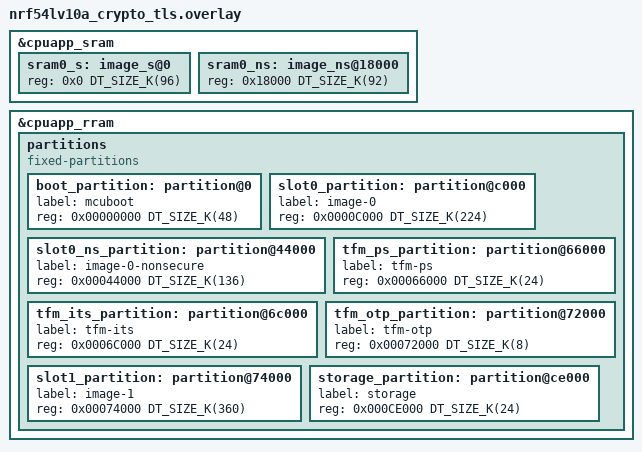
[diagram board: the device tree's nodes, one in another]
/*
 * Copyright (c) 2026 Nordic Semiconductor ASA
 *
 * SPDX-License-Identifier: LicenseRef-Nordic-5-Clause
 */

/*
 * Crypto/TLS-heavy TF-M partition layout for nRF54LV10A
 *
 * nRF54LV10A has 1012 kB of RRAM and 192 kB of SRAM.
 * TrustZone flash region alignment: 4 kB (MPC-based)
 * TrustZone RAM region alignment:   4 kB
 * RRAM erase-block-size:            4 kB
 *
 * Optimized for TLS/DTLS-heavy applications:
 * - Enlarged PS for X.509 certificate chains
 * - Enlarged ITS for TLS session keys and PSKs
 * - Full TF-M crypto for TLS 1.2/1.3
 * - MCUboot for secure firmware updates
 *
 * Suitable for: cloud-connected devices, HTTPS clients, MQTT+TLS
 */

&cpuapp_sram {
	sram0_s: image_s@0 {
		#address-cells = <1>;
		#size-cells = <1>;
		reg = <0x0 DT_SIZE_K(96)>;
		ranges = <0x0 0x0 DT_SIZE_K(96)>;
	};

	/* 92 kB NS — 4 kB unused at top */
	sram0_ns: image_ns@18000 {
		#address-cells = <1>;
		#size-cells = <1>;
		reg = <0x18000 DT_SIZE_K(92)>;
		ranges = <0x0 0x18000 DT_SIZE_K(92)>;
	};
};

&cpuapp_rram {
	partitions {
		compatible = "fixed-partitions";
		#address-cells = <1>;
		#size-cells = <1>;

		/*
		 * Flash layout (all addresses 4 kB aligned):
		 *
		 * 0x00000000  MCUboot bootloader        (48 kB)
		 * 0x0000C000  Primary slot:
		 *   0x0000C000  TF-M secure image       (224 kB)
		 *   0x00044000  Non-secure application   (136 kB)
		 * 0x00066000  TF-M PS                    (24 kB)
		 *             (enlarged for X.509 certificate chains)
		 * 0x0006C000  TF-M ITS                   (24 kB)
		 *             (enlarged for TLS session keys, PSKs)
		 * 0x00072000  TF-M OTP / NV counters      (8 kB)
		 * 0x00074000  Secondary slot            (360 kB)
		 * 0x000CE000  Non-secure storage         (24 kB)
		 *
		 * Primary = 224 + 136 = 360 kB = Secondary
		 * Total: 48 + 360 + 24 + 24 + 8 + 360 + 24 = 848 kB
		 */

		boot_partition: partition@0 {
			label = "mcuboot";
			reg = <0x00000000 DT_SIZE_K(48)>;
		};

		slot0_partition: partition@c000 {
			label = "image-0";
			reg = <0x0000C000 DT_SIZE_K(224)>;
		};

		slot0_ns_partition: partition@44000 {
			label = "image-0-nonsecure";
			reg = <0x00044000 DT_SIZE_K(136)>;
		};

		tfm_ps_partition: partition@66000 {
			label = "tfm-ps";
			reg = <0x00066000 DT_SIZE_K(24)>;
		};

		tfm_its_partition: partition@6c000 {
			label = "tfm-its";
			reg = <0x0006C000 DT_SIZE_K(24)>;
		};

		tfm_otp_partition: partition@72000 {
			label = "tfm-otp";
			reg = <0x00072000 DT_SIZE_K(8)>;
		};

		slot1_partition: partition@74000 {
			label = "image-1";
			reg = <0x00074000 DT_SIZE_K(360)>;
		};

		storage_partition: partition@ce000 {
			label = "storage";
			reg = <0x000CE000 DT_SIZE_K(24)>;
		};
	};
};
